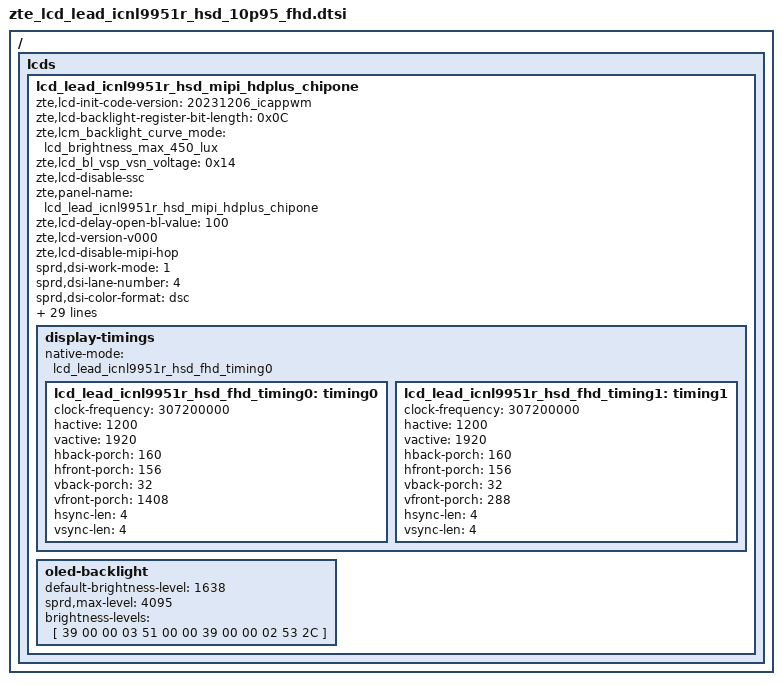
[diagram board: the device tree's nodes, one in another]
/ {
	fragment {
		target-path = "/";
		__overlay__ {
			lcds {
				lcd_lead_icnl9951r_hsd_mipi_hdplus_chipone: lcd_lead_icnl9951r_hsd_mipi_hdplus_chipone {
					zte,lcd-init-code-version = "20231206_icappwm";

					zte,lcd-backlight-register-bit-length = <0x0C>;
					zte,lcm_backlight_curve_mode = "lcd_brightness_max_450_lux";
					zte,lcd_bl_vsp_vsn_voltage = <0x14>;
					zte,lcd-disable-ssc;
					zte,panel-name = "lcd_lead_icnl9951r_hsd_mipi_hdplus_chipone";
					zte,lcd-delay-open-bl-value = <100>;
					zte,lcd-version-v000;
					zte,lcd-disable-mipi-hop;

					sprd,dsi-work-mode = <1>;
					sprd,dsi-lane-number = <4>;
					sprd,dsi-color-format = "dsc";
					sprd,dpi-clk-div = <0>;
					sprd,video-lp-cmd-enable = <0>;
					sprd,hporch-lp-disable = <0>;
					sprd,slice-width = <600>;
					sprd,slice-height = <8>;
					sprd,output-bpc = <8>;
					sprd,dsc-enable = <1>;
					sprd,dual-dsi-enable = <0>;

					sprd,phy-bit-clock = <896000>;
					sprd,phy-escape-clock = <20000>;/* kHz */

					sprd,width-mm = <147420>;
					sprd,height-mm = <235872>;

					sprd,esd-check-enable = <1>;/* 0:close , 1:open */
					sprd,esd-check-mode = <1>;/* 0:REG ,1:TE  */
					sprd,esd-check-period = <2000>;
					sprd,esd-check-register = <0x0A>;
					sprd,esd-check-value = <0x9C>;

					sprd,dphy-taget-val = <5>;

					sprd,reset-on-sequence = <1 5>, <0 2>, <1 11>;
					sprd,reset-off-sequence = <1 20>;

					sprd,use-gen-write;
					sprd,initial-command = [
						39 00 00 03 F0 5A 59
						39 00 00 03 F1 A5 A6
						39 00 00 21 B2 03 85 02 86 33 33 09 03 66 51 51 51 51 51 51 51 51 51 51 51 51 00 00 00 00 00 00 00 55 11 00 00
						39 00 00 21 B3 73 01 01 01 81 4B 00 00 51 00 00 11 34 01 01 01 01 00 00 00 00 00 00 00 03 06 80 80 01 00 00 00
						39 00 00 21 B4 0D 1F 0D 1F 56 26 01 3B BB EB FA DC A0 87 80 01 02 13 20 30 05 90 23 20 40 11 10 20 00 00 00 00
						39 00 00 21 B5 03 03 03 03 03 00 01 A8 A9 13 11 0F 0D 25 24 00 00 00 00 00 00 00 00 30 C0 00 00 00 FF FF FC 00
						39 00 00 21 B6 03 03 03 03 03 00 01 A8 A9 12 10 0E 0C 23 22 00 00 00 00 00 00 00 00 30 C0 00 00 00 FF FF FC 00
						39 00 00 1F B7 00 03 00 00 00 00 00 03 00 00 00 00 00 00 00 00 00 00 00 00 00 00 00 00 00 30 C0 00 00 00
						39 00 00 1F B8 00 03 00 00 00 00 00 03 00 00 00 00 00 00 00 00 00 00 00 00 00 00 00 00 00 30 C0 00 00 00
						39 00 00 21 B9 01 55 55 55 55 55 50 55 55 55 55 55 50 00 00 00 00 00 00 00 00 00 00 00 00 00 00 00 00 00 00 00
						39 00 00 10 BB 01 02 03 0A 04 13 14 12 16 5C 00 15 16 03 00
						39 00 00 1A BC FE F8 F0 00 00 00 00 04 00 05 80 02 24 00 99 99 99 00 C4 09 C3 86 03 2E 11
						39 00 00 09 BD EC 23 42 52 52 1F 00 00
						39 00 00 18 BE 6E 46 79 47 0A 88 58 33 33 33 93 00 E5 E5 00 00 00 00 B2 AF B2 AF 00
						39 00 00 0B BF 0C 19 0C 19 00 11 22 04 5D 07
						39 00 00 17 C0 40 90 17 12 34 F5 67 89 FF FF FF FF FF 3F 00 FF 00 CC 02 00 01 14
						39 00 00 17 C1 01 20 00 26 00 20 04 9C A0 04 C7 80 0F 0D C0 22 7F CF FF FF 0F E7
						39 00 00 09 C2 11 05 01 10 00 01 00 80
						39 00 00 21 C3 00 FF 42 4D 01 00 00 00 00 00 00 00 00 53 10 10 2A 2A 2A 2A 2A 2A 2A 2A 40 00 00 00 00 00 00 00
						39 00 00 0F C4 0C 35 28 49 00 3F 00 50 00 1F 00 22 F0 EF
						39 00 00 21 C5 03 13 10 56 5D 38 04 05 08 04 19 00 B4 2C 2B 2B BB AC 20 00 02 00 80 0F 0F 06 13 64 FF 03 20 FF
						39 00 00 1E C7 76 54 32 22 34 56 77 77 20 76 54 32 22 34 56 77 77 20 42 00 21 FF FF 04 04 03 0E 07 00
						39 00 00 21 80 E8 CD A6 85 6B 55 42 31 22 F0 CA A6 87 6B 52 21 F2 C8 A1 9F 7A 54 2C 00 D6 9F 7C 4E 41 3A 33 29
						39 00 00 21 81 E8 CA 9D 7C 63 4C 39 28 18 E8 C3 9F 80 65 4D 1B EC C3 9D 9B 76 51 29 FE D4 9E 7A 4C 40 39 32 28
						39 00 00 21 82 E8 CB A1 80 67 50 3D 2C 1D EC C6 A2 83 68 4F 1E EF C5 9F 9D 78 52 2A FF D5 9E 7B 4D 40 39 32 28
						39 00 00 1A 83 09 20 13 05 00 1F 12 05 00 1F 12 05 00 28 18 08 00 28 18 08 00 28 18 08 00
						39 00 00 1C 84 FF FF EA AA 55 55 00 00 00 FF FF EA AA 55 54 00 00 00 FF FF EA AA 55 54 00 00 00
						39 00 00 08 C8 42 00 48 E7 E0 00 23
						39 00 00 07 D7 3F 04 0A 00 00 0E
						39 00 00 04 D5 01 30 88
						39 00 00 03 F0 5A 57
						39 00 00 03 F1 A5 A7
						39 00 00 0E 79 41 12 00 00 00 00 97 02 00 20 00 03 02
						39 00 00 03 F0 5A 58
						39 00 00 03 F1 A5 A8
						39 00 00 0E 79 41 12 00 00 00 00 97 02 00 20 00 02 02
						39 00 00 03 F0 5A 59
						39 00 00 03 F1 A5 A6
						39 00 00 21 7A 11 00 00 89 30 80 07 80 04 B0 00 08 02 58 02 58 02 00 02 2C 00 20 00 C4 00 08 00 0C 0D B7 0B 71
						39 00 00 21 7B 18 00 10 F0 03 0C 20 00 06 0B 0B 33 0E 1C 2A 38 46 54 62 69 70 77 79 7B 7D 7E 01 02 01 00 09 40
						39 00 00 19 7C 09 BE 19 FC 19 FA 19 F8 1A 38 1A 78 1A B6 2A F6 2B 34 2B 74 3B 74 6B F4
						39 00 00 1A E0 0C 00 B8 10 00 0A BE 00 0B 05 01 00 1F 00 00 00 00 24 12 88 11 48 42 00 00
						15 00 00 02 36 03
						15 00 00 02 35 00
						39 00 00 03 51 00 00
						15 00 00 02 53 2C
						05 64 00 01 11
						05 14 00 01 29
						15 00 00 02 AC 05
						39 00 00 09 BD 2D 23 42 52 52 1F 00 00
						39 00 00 03 F1 5A 59
						39 01 00 03 F0 A5 A6
					];
					zte,initial-command-fps90 = [
						39 00 00 03 F0 5A 59
						39 00 00 03 F1 A5 A6
						39 00 00 21 B2 03 85 02 86 33 33 09 03 66 51 51 51 51 51 51 51 51 51 51 51 51 00 00 00 00 00 00 00 55 11 00 00
						39 00 00 21 B3 73 01 01 01 81 4B 00 00 51 00 00 11 34 01 01 01 01 00 00 00 00 00 00 00 03 06 80 80 01 00 00 00
						39 00 00 21 B4 0D 1F 0D 1F 56 26 01 3B BB EB FA DC A0 87 80 01 02 13 20 30 05 90 23 20 40 11 10 20 00 00 00 00
						39 00 00 21 B5 03 03 03 03 03 00 01 A8 A9 13 11 0F 0D 25 24 00 00 00 00 00 00 00 00 30 C0 00 00 00 FF FF FC 00
						39 00 00 21 B6 03 03 03 03 03 00 01 A8 A9 12 10 0E 0C 23 22 00 00 00 00 00 00 00 00 30 C0 00 00 00 FF FF FC 00
						39 00 00 1F B7 00 03 00 00 00 00 00 03 00 00 00 00 00 00 00 00 00 00 00 00 00 00 00 00 00 30 C0 00 00 00
						39 00 00 1F B8 00 03 00 00 00 00 00 03 00 00 00 00 00 00 00 00 00 00 00 00 00 00 00 00 00 30 C0 00 00 00
						39 00 00 21 B9 01 55 55 55 55 55 50 55 55 55 55 55 50 00 00 00 00 00 00 00 00 00 00 00 00 00 00 00 00 00 00 00
						39 00 00 10 BB 01 02 03 0A 04 13 14 12 16 5C 00 15 16 03 00
						39 00 00 1A BC FE F8 F0 00 00 00 00 04 00 05 80 02 24 00 99 99 99 00 C4 09 C3 86 03 2E 11
						39 00 00 09 BD EC 23 42 52 52 1F 00 00
						39 00 00 18 BE 6E 46 79 47 0A 88 58 33 33 33 93 00 E5 E5 00 00 00 00 B2 AF B2 AF 00
						39 00 00 0B BF 0C 19 0C 19 00 11 22 04 5D 07
						39 00 00 17 C0 40 90 17 12 34 F5 67 89 FF FF FF FF FF 3F 00 FF 00 CC 02 00 01 14
						39 00 00 17 C1 01 20 00 26 00 20 04 9C A0 04 C7 80 0F 0D C0 22 7F CF FF FF 0F E7
						39 00 00 09 C2 11 05 01 10 00 01 00 80
						39 00 00 21 C3 00 FF 42 4D 01 00 00 00 00 00 00 00 00 53 10 10 2A 2A 2A 2A 2A 2A 2A 2A 40 00 00 00 00 00 00 00
						39 00 00 0F C4 0C 35 28 49 00 3F 00 50 00 1F 00 22 F0 EF
						39 00 00 21 C5 03 13 10 56 5D 38 04 05 08 04 19 00 B4 2C 2B 2B BB AC 20 00 02 00 80 0F 0F 06 13 64 FF 03 20 FF
						39 00 00 1E C7 76 54 32 22 34 56 77 77 20 76 54 32 22 34 56 77 77 20 42 00 21 FF FF 04 04 03 0E 07 00
						39 00 00 21 80 E8 CD A6 85 6B 55 42 31 22 F0 CA A6 87 6B 52 21 F2 C8 A1 9F 7A 54 2C 00 D6 9F 7C 4E 41 3A 33 29
						39 00 00 21 81 E8 CA 9D 7C 63 4C 39 28 18 E8 C3 9F 80 65 4D 1B EC C3 9D 9B 76 51 29 FE D4 9E 7A 4C 40 39 32 28
						39 00 00 21 82 E8 CB A1 80 67 50 3D 2C 1D EC C6 A2 83 68 4F 1E EF C5 9F 9D 78 52 2A FF D5 9E 7B 4D 40 39 32 28
						39 00 00 1A 83 09 20 13 05 00 1F 12 05 00 1F 12 05 00 28 18 08 00 28 18 08 00 28 18 08 00
						39 00 00 1C 84 FF FF EA AA 55 55 00 00 00 FF FF EA AA 55 54 00 00 00 FF FF EA AA 55 54 00 00 00
						39 00 00 08 C8 42 00 48 E7 E0 00 23
						39 00 00 07 D7 3F 04 0A 00 00 0E
						39 00 00 04 D5 01 30 88
						39 00 00 03 F0 5A 57
						39 00 00 03 F1 A5 A7
						39 00 00 0E 79 41 12 00 00 00 00 97 02 00 20 00 03 02
						39 00 00 03 F0 5A 58
						39 00 00 03 F1 A5 A8
						39 00 00 0E 79 41 12 00 00 00 00 97 02 00 20 00 02 02
						39 00 00 03 F0 5A 59
						39 00 00 03 F1 A5 A6
						39 00 00 21 7A 11 00 00 89 30 80 07 80 04 B0 00 08 02 58 02 58 02 00 02 2C 00 20 00 C4 00 08 00 0C 0D B7 0B 71
						39 00 00 21 7B 18 00 10 F0 03 0C 20 00 06 0B 0B 33 0E 1C 2A 38 46 54 62 69 70 77 79 7B 7D 7E 01 02 01 00 09 40
						39 00 00 19 7C 09 BE 19 FC 19 FA 19 F8 1A 38 1A 78 1A B6 2A F6 2B 34 2B 74 3B 74 6B F4
						39 00 00 1A E0 0C 00 B8 10 00 0A BE 00 0B 05 01 00 1F 00 00 00 00 24 12 88 11 48 42 00 00
						15 00 00 02 36 03
						15 00 00 02 35 00
						39 00 00 03 51 00 00
						15 00 00 02 53 2C
						05 64 00 01 11
						05 14 00 01 29
						15 00 00 02 AC 05
						39 00 00 09 BD 2D 23 42 52 52 1F 00 00
						39 00 00 03 F1 5A 59
						39 01 00 03 F0 A5 A6
					];

					sprd,sleep-in-command = [
						15 01 00 02 AC 0A
						39 14 00 03 28 00 00
						39 78 00 03 10 00 00
						];
					sprd,sleep-out-command = [
						05 78 00 01 11
						05 14 00 01 29
						];
					display-timings {
						native-mode = <&lcd_lead_icnl9951r_hsd_fhd_timing0>;
						lcd_lead_icnl9951r_hsd_fhd_timing0: timing0 {
							clock-frequency = <307200000>;
							hactive = <1200>;
							vactive = <1920>;
							hback-porch = <160>;
							hfront-porch = <156>;
							vback-porch = <32>;
							vfront-porch = <1408>;
							hsync-len = <4>;
							vsync-len = <4>;
						};
						lcd_lead_icnl9951r_hsd_fhd_timing1: timing1 {
							clock-frequency = <307200000>;
							hactive = <1200>;
							vactive = <1920>;
							hback-porch = <160>;
							hfront-porch = <156>;
							vback-porch = <32>;
							vfront-porch = <288>;
							hsync-len = <4>;
							vsync-len = <4>;
						};
					};
					oled-backlight {
						default-brightness-level = <1638>;
						sprd,max-level = <4095>;
						brightness-levels = [
							39 00 00 03 51 00 00
							39 00 00 02 53 2C
						];
					};
				};
			};
		};
	};
};
